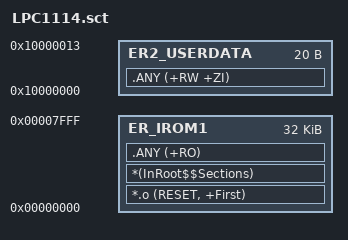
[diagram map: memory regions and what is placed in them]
; *************************************************************
; *** Scatter-Loading Description File generated by uVision ***
; *************************************************************

LR_IROM1 0x00000000 0x8000  {    ; load region size_region

  ER_IROM1 0x00000000 0x8000  {  ; load address = execution address
   *.o (RESET, +First)  ; startup vectors get placed at address 0x0 (first) 
   *(InRoot$$Sections)
;   IEC60335_B_RAMTestBIST.o (+RO)
   .ANY (+RO)
  }

  ER2_USERDATA 0x10000000 0x14 {
    IEC60335_B_UserData.o (UserData_noInit)
  }

  ER3_IRAM1 + 0x1FEC  {  ; RW data
   .ANY (+RW +ZI)
  }
}
